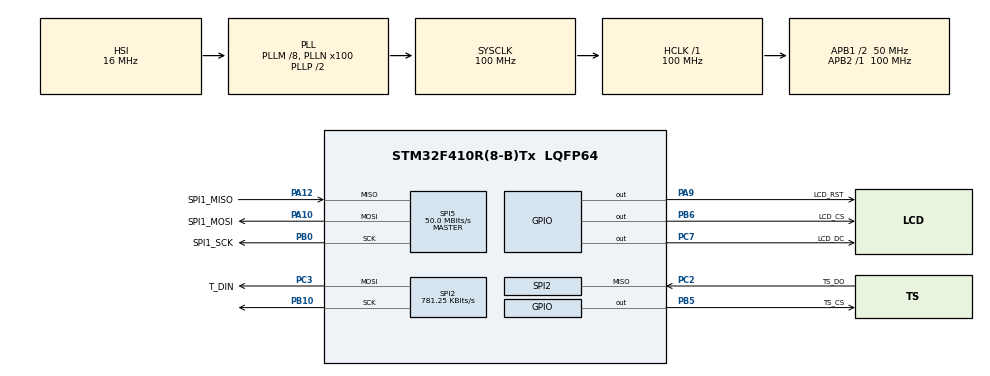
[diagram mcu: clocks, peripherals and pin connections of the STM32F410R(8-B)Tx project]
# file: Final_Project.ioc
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Mcu.Family=STM32F4
Mcu.Name=STM32F410R(8-B)Tx
Mcu.Package=LQFP64
NVIC.PriorityGroup=NVIC_PRIORITYGROUP_0
PA10.GPIO_Label=SPI1_MOSI
PA10.Mode=Full_Duplex_Master
PA10.Signal=SPI5_MOSI
PA12.GPIO_Label=SPI1_MISO
PA12.Mode=Full_Duplex_Master
PA12.Signal=SPI5_MISO
PA9.GPIO_Label=LCD_RST
PA9.Signal=GPIO_Output
PB0.GPIO_Label=SPI1_SCK
PB0.Mode=Full_Duplex_Master
PB0.Signal=SPI5_SCK
PB10.Mode=Full_Duplex_Master
PB10.Signal=SPI2_SCK
PB5.GPIO_Label=TS_CS
PB5.Signal=GPIO_Output
PB6.GPIO_Label=LCD_CS
PB6.Signal=GPIO_Output
PC2.GPIO_Label=TS_DO
PC2.Mode=Full_Duplex_Master
PC2.Signal=SPI2_MISO
PC3.GPIO_Label=T_DIN
PC3.Mode=Full_Duplex_Master
PC3.Signal=SPI2_MOSI
PC7.GPIO_Label=LCD_DC
PC7.Signal=GPIO_Output
ProjectManager.HeapSize=0x200
ProjectManager.StackSize=0x400
ProjectManager.TargetToolchain=STM32CubeIDE
RCC.48MHZClocksFreq_Value=50000000
RCC.AHBFreq_Value=100000000
RCC.APB1CLKDivider=RCC_HCLK_DIV2
RCC.APB1Freq_Value=50000000
RCC.APB1TimFreq_Value=100000000
RCC.APB2Freq_Value=100000000
RCC.APB2TimFreq_Value=100000000
RCC.CortexFreq_Value=100000000
RCC.FLatency-AdvancedSettings=FLASH_LATENCY_3
RCC.HCLKFreq_Value=100000000
RCC.HSE_VALUE=8000000
RCC.HSI_VALUE=16000000
RCC.PLLM=8
RCC.PLLN=100
RCC.SYSCLKFreq_VALUE=100000000
RCC.SYSCLKSource=RCC_SYSCLKSOURCE_PLLCLK
RCC.VCOOutputFreq_Value=200000000
SPI2.BaudRatePrescaler=SPI_BAUDRATEPRESCALER_64
SPI2.CalculateBaudRate=781.25 KBits/s
SPI2.Direction=SPI_DIRECTION_2LINES
SPI2.Mode=SPI_MODE_MASTER
SPI2.VirtualType=VM_MASTER
SPI5.CalculateBaudRate=50.0 MBits/s
SPI5.Direction=SPI_DIRECTION_2LINES
SPI5.Mode=SPI_MODE_MASTER
SPI5.VirtualType=VM_MASTER
board=NUCLEO-F410RB

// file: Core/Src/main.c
/* USER CODE BEGIN Header */
/**
  ******************************************************************************
  * @file           : main.c
  * @brief          : Main program body
  ******************************************************************************
  * @attention
  *
  * <h2><center>&copy; Copyright (c) 2020 STMicroelectronics.
  * All rights reserved.</center></h2>
  *
  * This software component is licensed by ST under BSD 3-Clause license,
  * the "License"; You may not use this file except in compliance with the
  * License. You may obtain a copy of the License at:
  *                        opensource.org/licenses/BSD-3-Clause
  *
  ******************************************************************************
  */
/* USER CODE END Header */
#include "main.h"

/* USER CODE BEGIN Includes */
#include "MY_ILI9341.h"
#include "TSC2046.h"
/* USER CODE END Includes */

SPI_HandleTypeDef hspi2;
SPI_HandleTypeDef hspi5;

void SystemClock_Config(void);
static void MX_GPIO_Init(void);
static void MX_SPI2_Init(void);
static void MX_SPI5_Init(void);

int main(void)
{

  /* MCU Configuration--------------------------------------------------------*/

  /* Reset of all peripherals, Initializes the Flash interface and the Systick. */
  HAL_Init();

  /* Configure the system clock */
  SystemClock_Config();

  /* Initialize all configured peripherals */
  MX_GPIO_Init();
  MX_SPI2_Init();
  MX_SPI5_Init();
  /* USER CODE BEGIN 2 */
ILI9341_Init(&hspi5, LCD_CS_GPIO_Port, LCD_CS_Pin, LCD_DC_GPIO_Port, LCD_DC_Pin, LCD_RST_GPIO_Port, LCD_RST_Pin);
ILI9341_setRotation(2);
ILI9341_Fill(COLOR_NAVY);

TSC2046_Begin(&hspi2, TS_CS_GPIO_Port, TS_CS_Pin);
TSC2046_Calibrate();
ILI9341_Fill(COLOR_NAVY);
  /* USER CODE END 2 */

  /* Infinite loop */
  while (1)
  {

  }
}

void SystemClock_Config(void)
{
  RCC_OscInitTypeDef RCC_OscInitStruct = {0};
  RCC_ClkInitTypeDef RCC_ClkInitStruct = {0};

  /** Configure the main internal regulator output voltage
  */
  __HAL_RCC_PWR_CLK_ENABLE();
  __HAL_PWR_VOLTAGESCALING_CONFIG(PWR_REGULATOR_VOLTAGE_SCALE1);
  /** Initializes the RCC Oscillators according to the specified parameters
  * in the RCC_OscInitTypeDef structure.
  */
  RCC_OscInitStruct.OscillatorType = RCC_OSCILLATORTYPE_HSI;
  RCC_OscInitStruct.HSIState = RCC_HSI_ON;
  RCC_OscInitStruct.HSICalibrationValue = RCC_HSICALIBRATION_DEFAULT;
  RCC_OscInitStruct.PLL.PLLState = RCC_PLL_ON;
  RCC_OscInitStruct.PLL.PLLSource = RCC_PLLSOURCE_HSI;
  RCC_OscInitStruct.PLL.PLLM = 8;
  RCC_OscInitStruct.PLL.PLLN = 100;
  RCC_OscInitStruct.PLL.PLLP = RCC_PLLP_DIV2;
  RCC_OscInitStruct.PLL.PLLQ = 4;
  RCC_OscInitStruct.PLL.PLLR = 2;
  if (HAL_RCC_OscConfig(&RCC_OscInitStruct) != HAL_OK)
  {
    Error_Handler();
  }
  /** Initializes the CPU, AHB and APB buses clocks
  */
  RCC_ClkInitStruct.ClockType = RCC_CLOCKTYPE_HCLK|RCC_CLOCKTYPE_SYSCLK
                              |RCC_CLOCKTYPE_PCLK1|RCC_CLOCKTYPE_PCLK2;
  RCC_ClkInitStruct.SYSCLKSource = RCC_SYSCLKSOURCE_PLLCLK;
  RCC_ClkInitStruct.AHBCLKDivider = RCC_SYSCLK_DIV1;
  RCC_ClkInitStruct.APB1CLKDivider = RCC_HCLK_DIV2;
  RCC_ClkInitStruct.APB2CLKDivider = RCC_HCLK_DIV1;

  if (HAL_RCC_ClockConfig(&RCC_ClkInitStruct, FLASH_LATENCY_3) != HAL_OK)
  {
    Error_Handler();
  }
}

static void MX_SPI2_Init(void)
{

  /* SPI2 parameter configuration*/
  hspi2.Instance = SPI2;
  hspi2.Init.Mode = SPI_MODE_MASTER;
  hspi2.Init.Direction = SPI_DIRECTION_2LINES;
  hspi2.Init.DataSize = SPI_DATASIZE_8BIT;
  hspi2.Init.CLKPolarity = SPI_POLARITY_LOW;
  hspi2.Init.CLKPhase = SPI_PHASE_1EDGE;
  hspi2.Init.NSS = SPI_NSS_SOFT;
  hspi2.Init.BaudRatePrescaler = SPI_BAUDRATEPRESCALER_64;
  hspi2.Init.FirstBit = SPI_FIRSTBIT_MSB;
  hspi2.Init.TIMode = SPI_TIMODE_DISABLE;
  hspi2.Init.CRCCalculation = SPI_CRCCALCULATION_DISABLE;
  hspi2.Init.CRCPolynomial = 15;
  if (HAL_SPI_Init(&hspi2) != HAL_OK)
  {
    Error_Handler();
  }

}

static void MX_SPI5_Init(void)
{

  /* SPI5 parameter configuration*/
  hspi5.Instance = SPI5;
  hspi5.Init.Mode = SPI_MODE_MASTER;
  hspi5.Init.Direction = SPI_DIRECTION_2LINES;
  hspi5.Init.DataSize = SPI_DATASIZE_8BIT;
  hspi5.Init.CLKPolarity = SPI_POLARITY_LOW;
  hspi5.Init.CLKPhase = SPI_PHASE_1EDGE;
  hspi5.Init.NSS = SPI_NSS_SOFT;
  hspi5.Init.BaudRatePrescaler = SPI_BAUDRATEPRESCALER_2;
  hspi5.Init.FirstBit = SPI_FIRSTBIT_MSB;
  hspi5.Init.TIMode = SPI_TIMODE_DISABLE;
  hspi5.Init.CRCCalculation = SPI_CRCCALCULATION_DISABLE;
  hspi5.Init.CRCPolynomial = 15;
  if (HAL_SPI_Init(&hspi5) != HAL_OK)
  {
    Error_Handler();
  }

}

static void MX_GPIO_Init(void)
{
  GPIO_InitTypeDef GPIO_InitStruct = {0};

  /* GPIO Ports Clock Enable */
  __HAL_RCC_GPIOC_CLK_ENABLE();
  __HAL_RCC_GPIOB_CLK_ENABLE();
  __HAL_RCC_GPIOA_CLK_ENABLE();

  /*Configure GPIO pin Output Level */
  HAL_GPIO_WritePin(LCD_DC_GPIO_Port, LCD_DC_Pin, GPIO_PIN_RESET);

  /*Configure GPIO pin Output Level */
  HAL_GPIO_WritePin(LCD_RST_GPIO_Port, LCD_RST_Pin, GPIO_PIN_RESET);

  /*Configure GPIO pin Output Level */
  HAL_GPIO_WritePin(GPIOB, TS_CS_Pin|LCD_CS_Pin, GPIO_PIN_RESET);

  /*Configure GPIO pin : LCD_DC_Pin */
  GPIO_InitStruct.Pin = LCD_DC_Pin;
  GPIO_InitStruct.Mode = GPIO_MODE_OUTPUT_PP;
  GPIO_InitStruct.Pull = GPIO_NOPULL;
  GPIO_InitStruct.Speed = GPIO_SPEED_FREQ_LOW;
  HAL_GPIO_Init(LCD_DC_GPIO_Port, &GPIO_InitStruct);

  /*Configure GPIO pin : LCD_RST_Pin */
  GPIO_InitStruct.Pin = LCD_RST_Pin;
  GPIO_InitStruct.Mode = GPIO_MODE_OUTPUT_PP;
  GPIO_InitStruct.Pull = GPIO_NOPULL;
  GPIO_InitStruct.Speed = GPIO_SPEED_FREQ_LOW;
  HAL_GPIO_Init(LCD_RST_GPIO_Port, &GPIO_InitStruct);

  /*Configure GPIO pins : TS_CS_Pin LCD_CS_Pin */
  GPIO_InitStruct.Pin = TS_CS_Pin|LCD_CS_Pin;
  GPIO_InitStruct.Mode = GPIO_MODE_OUTPUT_PP;
  GPIO_InitStruct.Pull = GPIO_NOPULL;
  GPIO_InitStruct.Speed = GPIO_SPEED_FREQ_LOW;
  HAL_GPIO_Init(GPIOB, &GPIO_InitStruct);

}

void Error_Handler(void)
{
}

/************************ (C) COPYRIGHT STMicroelectronics *****END OF FILE****/
